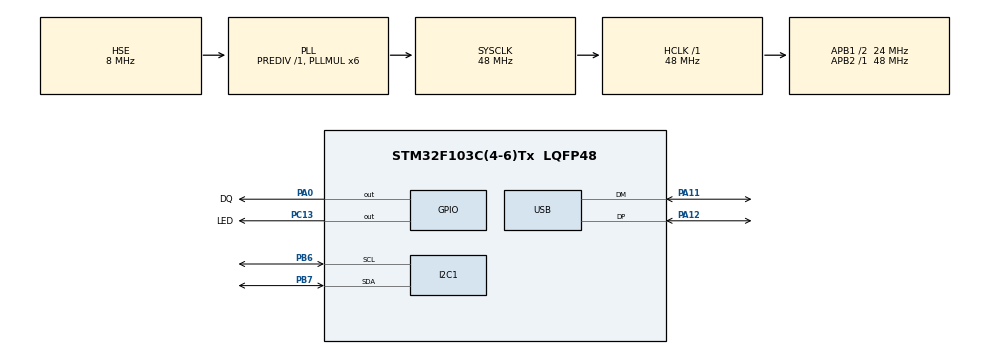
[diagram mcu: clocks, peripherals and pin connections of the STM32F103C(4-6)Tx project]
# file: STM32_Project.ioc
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Mcu.Family=STM32F1
Mcu.Name=STM32F103C(4-6)Tx
Mcu.Package=LQFP48
NVIC.PriorityGroup=NVIC_PRIORITYGROUP_4
NVIC.USB_LP_CAN1_RX0_IRQn=true\:0\:0\:false\:false\:true\:false\:true\:true
PA0-WKUP.GPIO_Label=DQ
PA0-WKUP.GPIO_Speed=GPIO_SPEED_FREQ_MEDIUM
PA0-WKUP.PinState=GPIO_PIN_RESET
PA0-WKUP.Signal=GPIO_Output
PA11.Mode=Device
PA11.Signal=USB_DM
PA12.Mode=Device
PA12.Signal=USB_DP
PA13.Mode=Serial_Wire
PA13.Signal=SYS_JTMS-SWDIO
PA14.Mode=Serial_Wire
PA14.Signal=SYS_JTCK-SWCLK
PB6.GPIO_Pu=GPIO_PULLUP
PB6.Mode=I2C
PB6.Signal=I2C1_SCL
PB7.GPIO_Pu=GPIO_PULLUP
PB7.Mode=I2C
PB7.Signal=I2C1_SDA
PC13-TAMPER-RTC.GPIO_Label=LED
PC13-TAMPER-RTC.GPIO_ModeDefaultOutputPP=GPIO_MODE_OUTPUT_OD
PC13-TAMPER-RTC.GPIO_PuPd=GPIO_PULLUP
PC13-TAMPER-RTC.PinState=GPIO_PIN_SET
PC13-TAMPER-RTC.Signal=GPIO_Output
PD0-OSC_IN.Mode=HSE-External-Oscillator
PD0-OSC_IN.Signal=RCC_OSC_IN
PD1-OSC_OUT.Mode=HSE-External-Oscillator
PD1-OSC_OUT.Signal=RCC_OSC_OUT
ProjectManager.HeapSize=0x200
ProjectManager.StackSize=0x400
ProjectManager.TargetToolchain=STM32CubeIDE
RCC.AHBFreq_Value=48000000
RCC.APB1CLKDivider=RCC_HCLK_DIV2
RCC.APB1Freq_Value=24000000
RCC.APB1TimFreq_Value=48000000
RCC.APB2Freq_Value=48000000
RCC.APB2TimFreq_Value=48000000
RCC.HCLKFreq_Value=48000000
RCC.PLLMUL=RCC_PLL_MUL6
RCC.SYSCLKFreq_VALUE=48000000
RCC.SYSCLKSource=RCC_SYSCLKSOURCE_PLLCLK
RCC.USBFreq_Value=48000000
USB_DEVICE.CLASS_NAME_FS=CDC
USB_DEVICE.VID=1155
USB_DEVICE.VirtualMode=Cdc
USB_DEVICE.VirtualModeFS=Cdc_FS
VP_USB_DEVICE_VS_USB_DEVICE_CDC_FS.Mode=CDC_FS
board=custom

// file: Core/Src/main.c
/* USER CODE BEGIN Header */
/**
  ******************************************************************************
  * @file           : main.c
  * @brief          : Main program body
  ******************************************************************************
  * @attention
  *
  * Copyright (c) 2023 STMicroelectronics.
  * All rights reserved.
  *
  * This software is licensed under terms that can be found in the LICENSE file
  * in the root directory of this software component.
  * If no LICENSE file comes with this software, it is provided AS-IS.
  *
  ******************************************************************************
  */
/* USER CODE END Header */
#include "main.h"
#include "i2c.h"
#include "usb_device.h"
#include "gpio.h"

/* USER CODE BEGIN Includes */
#include "usbd_cdc_if.h"
#include "../../Drivers/DS18B20/ds18b20.h"
#include "../../Drivers/OLED/oled.h"
/* USER CODE END Includes */

void SystemClock_Config(void);

int main(void) {

    /* MCU Configuration--------------------------------------------------------*/

    /* Reset of all peripherals, Initializes the Flash interface and the Systick. */
    HAL_Init();

    /* Configure the system clock */
    SystemClock_Config();

    /* Initialize all configured peripherals */
    MX_GPIO_Init();
    MX_USB_DEVICE_Init();
    MX_I2C1_Init();
    /* USER CODE BEGIN 2 */
    HAL_GPIO_WritePin(LED_GPIO_Port, LED_Pin, GPIO_PIN_SET);
    OLED_Init();
    /* USER CODE END 2 */

    /* Infinite loop */
    /* USER CODE BEGIN WHILE */
    OLED_Route_180(1);
    OLED_Show_String(0, 0, "Hello World.", 16, 1);
    OLED_Refresh();
    while (1) {
        HAL_GPIO_TogglePin(LED_GPIO_Port, LED_Pin);
        HAL_Delay(1000);
        /* USER CODE END WHILE */

    }
}

void SystemClock_Config(void) {
    RCC_OscInitTypeDef RCC_OscInitStruct = {0};
    RCC_ClkInitTypeDef RCC_ClkInitStruct = {0};
    RCC_PeriphCLKInitTypeDef PeriphClkInit = {0};

    /** Initializes the RCC Oscillators according to the specified parameters
    * in the RCC_OscInitTypeDef structure.
    */
    RCC_OscInitStruct.OscillatorType = RCC_OSCILLATORTYPE_HSE;
    RCC_OscInitStruct.HSEState = RCC_HSE_ON;
    RCC_OscInitStruct.HSEPredivValue = RCC_HSE_PREDIV_DIV1;
    RCC_OscInitStruct.HSIState = RCC_HSI_ON;
    RCC_OscInitStruct.PLL.PLLState = RCC_PLL_ON;
    RCC_OscInitStruct.PLL.PLLSource = RCC_PLLSOURCE_HSE;
    RCC_OscInitStruct.PLL.PLLMUL = RCC_PLL_MUL6;
    if (HAL_RCC_OscConfig(&RCC_OscInitStruct) != HAL_OK) {
        Error_Handler();
    }

    /** Initializes the CPU, AHB and APB buses clocks
    */
    RCC_ClkInitStruct.ClockType = RCC_CLOCKTYPE_HCLK | RCC_CLOCKTYPE_SYSCLK
                                  | RCC_CLOCKTYPE_PCLK1 | RCC_CLOCKTYPE_PCLK2;
    RCC_ClkInitStruct.SYSCLKSource = RCC_SYSCLKSOURCE_PLLCLK;
    RCC_ClkInitStruct.AHBCLKDivider = RCC_SYSCLK_DIV1;
    RCC_ClkInitStruct.APB1CLKDivider = RCC_HCLK_DIV2;
    RCC_ClkInitStruct.APB2CLKDivider = RCC_HCLK_DIV1;

    if (HAL_RCC_ClockConfig(&RCC_ClkInitStruct, FLASH_LATENCY_1) != HAL_OK) {
        Error_Handler();
    }
    PeriphClkInit.PeriphClockSelection = RCC_PERIPHCLK_USB;
    PeriphClkInit.UsbClockSelection = RCC_USBCLKSOURCE_PLL;
    if (HAL_RCCEx_PeriphCLKConfig(&PeriphClkInit) != HAL_OK) {
        Error_Handler();
    }
}

void Error_Handler(void) {
    /* USER CODE BEGIN Error_Handler_Debug */
    /* User can add his own implementation to report the HAL error return state */
    __disable_irq();
    while (1) {
        HAL_GPIO_WritePin(LED_GPIO_Port, LED_Pin, GPIO_PIN_RESET);
    }
    /* USER CODE END Error_Handler_Debug */
}
